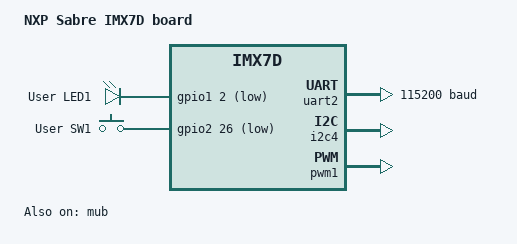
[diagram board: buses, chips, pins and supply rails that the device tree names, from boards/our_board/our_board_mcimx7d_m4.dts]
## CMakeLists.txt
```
cmake_minimum_required(VERSION 3.20.0)

find_package(Zephyr REQUIRED)
project(my_zephyr_app)

target_sources(app PRIVATE src/main.cpp)

add_subdirectory(drivers/iomico_myled)
```

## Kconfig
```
menuconfig LED_SUBSYSTEM
    bool "LED Subsystem"

if LED_SUBSYSTEM

    config APP_HEARTBEAT_PERIOD_MS
        int "App heartbeat period (100-2000)"
        range 100 2000
        default 500

    choice
        prompt "LED blink sleep time (1s (medium))"
        default BLINK_SLEEP_MEDIUM

        config BLINK_SLEEP_SLOW
            bool "2s (slow)"
        config BLINK_SLEEP_MEDIUM
            bool "1s (medium)"
        config BLINK_SLEEP_FAST
            bool "250ms (fast)"
    endchoice

    config BLINK_SLEEP_TIME_MS
        int
        default 250 if BLINK_SLEEP_FAST
        default 1000 if BLINK_SLEEP_MEDIUM
        default 2000 if BLINK_SLEEP_SLOW
        default 0

    menuconfig LED_ADVANCED
        bool "Advanced LED settings"

        if LED_ADVANCED

            config LED_BRIGHTNESS
                int "LED brightness (0-100)"
                range 0 100
                default 100

            config LED_FADE_DURATION_MS
                int "Fade duration (ms)"
                range 0 5000
                default 500

            menu "Expert settings"
            
                config LED_DEBUGGING
                    bool "Enable LED debugging"

                config LED_CUSTOM_BLINK
                    bool "Custom blink pattern"

            endmenu
        
        endif

endif

source "Kconfig.zephyr"
rsource "drivers/iomico_myled/Kconfig"
```

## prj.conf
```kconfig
CONFIG_GPIO=y
CONFIG_LOG=y
CONFIG_LED_SUBSYSTEM=y
CONFIG_IOMICO_MYLED=y
CONFIG_SHELL=y
CONFIG_NATIVE_UART_0_ON_STDINOUT=y
```

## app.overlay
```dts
/ {
	aliases {
		app-led = &led0;
	};
	iomico_myled0: iomico_myled0 {
		compatible = "iomico,myled";
		status = "okay";
		gpios = <&gpio0 18 GPIO_ACTIVE_LOW>;
	};
	iomico_myled1: iomico_myled1 {
		compatible = "iomico,myled";
		status = "okay";
		gpios = <&gpio0 19 GPIO_ACTIVE_LOW>;
	};
};
```

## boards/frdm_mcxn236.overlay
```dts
/ {
	aliases {
		app-led = &red_led;
	};
	iomico_myled0: iomico_myled0 {
		compatible = "iomico,myled";
		status = "okay";
		gpios = <&gpio4 18 GPIO_ACTIVE_LOW>;
	};
	iomico_myled1: iomico_myled1 {
		compatible = "iomico,myled";
		status = "okay";
		gpios = <&gpio4 19 GPIO_ACTIVE_LOW>;
	};
};
```

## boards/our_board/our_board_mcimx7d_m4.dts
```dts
/*
 * Copyright (c) 2017,2019 NXP
 *
 * SPDX-License-Identifier: Apache-2.0
 */

/dts-v1/;

#include <nxp/nxp_imx7d_m4.dtsi>
#include "colibri_imx7d-pinctrl.dtsi"
#include <zephyr/dt-bindings/input/input-event-codes.h>

/ {
	model = "NXP Sabre IMX7D board";
	compatible = "nxp,mcimx7d_m4";

	aliases {
		led0   = &green_led;
		sw0    = &user_switch_1;
	};

	chosen {
		zephyr,flash = &tcml_code;
		zephyr,sram = &tcmu_sys;
		zephyr,console = &uart2;
		zephyr,shell-uart = &uart2;
	};

	leds {
		compatible = "gpio-leds";
		green_led: led_0 {
			gpios = <&gpio1 2 GPIO_ACTIVE_LOW>;
			label = "User LED1";
		};
	};

	gpio_keys {
		compatible = "gpio-keys";
		user_switch_1: user_sw_1 {
			gpios = <&gpio2 26 (GPIO_ACTIVE_LOW | GPIO_PULL_UP)>;
			label = "User SW1";
			zephyr,code = <INPUT_KEY_0>;
		};
	};
};

&uart2 {
	status = "okay";
	current-speed = <115200>;
	modem-mode = <64>;
	pinctrl-0 = <&uart2_default>;
	pinctrl-names = "default";
};

&gpio1 {
	status = "okay";
};

&gpio2 {
	status = "okay";
};

&i2c1 {
	pinctrl-0 = <&i2c1_default>;
	pinctrl-names = "default";
};

&i2c2 {
	pinctrl-0 = <&i2c2_default>;
	pinctrl-names = "default";
};

&i2c3 {
	pinctrl-0 = <&i2c3_default>;
	pinctrl-names = "default";
};

&i2c4 {
	pinctrl-0 = <&i2c4_default>;
	pinctrl-names = "default";
	status = "okay";
};

&pwm1 {
	pinctrl-0 = <&pwm1_default>;
	pinctrl-names = "default";
	status = "okay";
};

&pwm2 {
	pinctrl-0 = <&pwm2_default>;
	pinctrl-names = "default";
};

&pwm3 {
	pinctrl-0 = <&pwm3_default>;
	pinctrl-names = "default";
};

&pwm4 {
	pinctrl-0 = <&pwm4_default>;
	pinctrl-names = "default";
};

&mub {
	status = "okay";
};
```

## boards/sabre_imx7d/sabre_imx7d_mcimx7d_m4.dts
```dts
/dts-v1/;

#include <nxp/nxp_imx7d_m4.dtsi>
#include <nxp/nxp_imx/mimx7d-pinctrl.dtsi>

/ {
	model = "NXP Sabre IMX7D board";
	compatible = "nxp,mcimx7d_m4";

	aliases {
		led0   = &green_led;
	};

	chosen {
		zephyr,flash = &tcml_code;
		zephyr,sram = &tcmu_sys;
	};

	leds {
		compatible = "gpio-leds";
		green_led: led_0 {
			gpios = <&gpio1 2 GPIO_ACTIVE_LOW>;
			label = "User LED1";
		};
	};
};

&gpio1 {
	status = "okay";
};
```

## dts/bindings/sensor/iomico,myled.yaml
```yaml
description: Iomico MyLed GPIO-driven LED (course sensor-style driver)

compatible: "iomico,myled"

include: base.yaml

properties:
  gpios:
    type: phandle-array
    required: true
    description: GPIO used to drive the LED.
```

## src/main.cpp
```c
#include <zephyr/drivers/gpio.h>
#include <zephyr/kernel.h>
#include <zephyr/logging/log.h>
#include "iomico_myled.h"

/* The devicetree node identifier for the "led0" alias. */
#define LED_NODE DT_ALIAS(app_led)

static const struct gpio_dt_spec led = GPIO_DT_SPEC_GET(LED_NODE, gpios);

LOG_MODULE_REGISTER(main, LOG_LEVEL_INF);

namespace {
    void test() {
        const struct device* driver0 = DEVICE_DT_GET(DT_NODELABEL(iomico_myled0));
        const struct device* driver1 = DEVICE_DT_GET(DT_NODELABEL(iomico_myled1));
        
        LOG_INF("Calling iomico_myled_state_on (turn LEDs ON)...");
        auto ret1 = iomico_myled_state_on(driver0);
        auto ret2 = iomico_myled_state_on(driver1);
        LOG_INF("iomico_myled_state_on Return: %d %d", ret1, ret2);
        
        k_msleep(500);
        
        LOG_INF("Calling iomico_myled_state_off (turn LEDs OFF)...");
        ret1 = iomico_myled_state_off(driver0);
        ret2 = iomico_myled_state_off(driver1);
        LOG_INF("iomico_myled_state_off Return: %d %d", ret1, ret2);
    }
}

int main(void)
{
    if (!gpio_is_ready_dt(&led)) return 0;

    if (gpio_pin_configure_dt(&led, GPIO_OUTPUT_ACTIVE) < 0) return 0;

    test();

    int32_t beat_ms = CONFIG_APP_HEARTBEAT_PERIOD_MS * 15 / 100;
    int32_t sleep_ms = CONFIG_APP_HEARTBEAT_PERIOD_MS - (beat_ms * 4);

    LOG_INF("beat_ms:%d sleep_ms:%d\n", beat_ms, sleep_ms);

    uint8_t cnt = 0;
    bool heartbeat = true;
    while (1) {
        if (heartbeat) {
            if (gpio_pin_set_dt(&led, 1) < 0) return 0;
            k_msleep(beat_ms);
            if (gpio_pin_set_dt(&led, 0) < 0) return 0;
            k_msleep(beat_ms);
            if (gpio_pin_set_dt(&led, 1) < 0) return 0;
            k_msleep(beat_ms);
            if (gpio_pin_set_dt(&led, 0) < 0) return 0;
            k_msleep(beat_ms);

            LOG_INF("LED heartbeat #%d!", ++cnt);
            if (cnt >= 10) heartbeat = false;
        }
        
        k_msleep(sleep_ms);
    }
    return 0;
}
```
